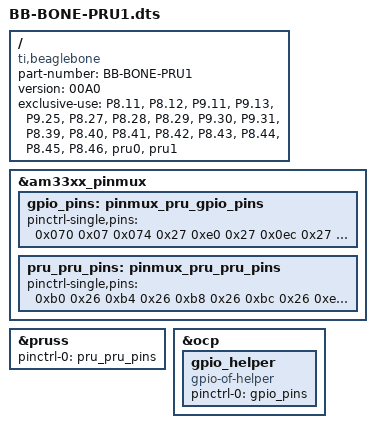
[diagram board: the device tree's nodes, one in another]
/dts-v1/;
/plugin/;

/ {
        compatible = "ti,beaglebone", "ti,beaglebone-black";
        part-number = "BB-BONE-PRU1";
        version = "00A0";
        exclusive-use = "P8.11",                        
                        "P8.12",
                        "P9.11",
                        "P9.13",
                        "P9.25",
                        "P8.27",
                        "P8.28", 
                        "P8.29",
                        "P9.30",
                        "P9.31",
                        "P8.39",
                        "P8.40",
                        "P8.41",
                        "P8.42",
                        "P8.43",
                        "P8.44",
                        "P8.45",
                        "P8.46",
                        "pru0",
                        "pru1";

        fragment@0 {
                target = <&am33xx_pinmux>;
                __overlay__ {

                        gpio_pins: pinmux_pru_gpio_pins {
                                pinctrl-single,pins = <0x070 0x07  //P9_11 MODE7 GPIO output pull-down
                                                       0x074 0x27  //P9_13 MODE7 GPIO input pull-down
                                                       0xe0 0x27   //P8_27 MODE7 GPIO output pull-down $PINS 
                                                       0x0ec 0x27  //P8_30 MODE7 GPIO output pull-down $PINS 59
                                                       0x0d8 0x27  //P8_31 MODE7 GPIO output pull-down $PINS 54
                                                       0x0dc 0x27  //P8_32 MODE7 GPIO output pull-down $PINS 55
                                                       0x0d4 0x27  //P8_33 MODE7 GPIO output pull-down $PINS 53
                                                       0x0cc 0x27  //P8_34 MODE7 GPIO output pull-down $PINS 51
                                                       0x0d0 0x27  //P8_35 MODE7 GPIO output pull-down $PINS 52
                                                       0x0c8 0x27  //P8_36 MODE7 GPIO output pull-down $PINS 50
                                                       0x0c0 0x27  //P8_37 MODE7 GPIO output pull-down $PINS 48
                                                       0x0c4 0x27  //P8_38 MODE7 GPIO output pull-down $PINS 49
                                                      >;
                        };

                        pru_pru_pins: pinmux_pru_pru_pins {
                                pinctrl-single,pins = <// 0x80 0x25 //this pin appears to conflict with the eMMC
                                                       // 0x84 0x25 //this pin appears to conflict with the eMMC
                                                       0xb0 0x26  //P8_41 r31.4  input pull-down $PINS 44
                                                       0xb4 0x26  //P8_42 r31.5  input pull-down $PINS 45
                                                       0xb8 0x26  //P8_39 r31.6  input pull-down $PINS 42
                                                       0xbc 0x26  //P8_40 r31.7  input pull-down $PINS 47
                                                       //0xe0 0x05  //P8_27 r31.8  output pull-down $PINS 56
                                                       0xe4 0x26  //P8_29 r31.9  input pull-down $PINS 57
                                                       0xe8 0x26  //P8_28 r31.10 input pull-down $PINS 58
                                                       0xa0 0x26  //P8_45 r31.0  input pull-down $PINS 40
                                                       0xa4 0x26  //P8_46 r31.1  input pull-down $PINS 41
                                                       0xa8 0x26  //P8_43 r31.2  input pull-down $PINS 42
                                                       0xac 0x26  //P8_44 r31.3  input pull-down $PINS 43

                                                       0x034 0x06  // P8_11 pr1_pru0_pru_r30_15, MODE6 | OUTPUT | PRU
                                                       0x030 0x06  // P8_12 pr1_pru0_pru_r30_14, MODE6 | OUTPUT | PRU
                                                       0x1ac 0x05  // P9_25 pr1_pru0_pru_r30_7, MODE5 | OUTPUT | PRU
                                                       0x190 0x05  // P9_31 pr1_pru0_pru_r30_0, MODE5 | OUTPUT | PRU

                                                       0x1A4 0x26  // P9_27 pr1_pru0_pru_r31_5, MODE6 | INPUT | PRU
                                                       0x19c 0x26  // P9_28 pr1_pru0_pru_r31_3, MODE6 | INPUT | PRU
                                                       0x194 0x26  // P9_29 pr1_pru0_pru_r31_1 , MODE 6 | INPUT | PRU
                                                       0x198 0x26  // P9_30 pr1_pru0_pru_r31_2 , MODE 6 | INPUT | PRU 
                                                       >;
                                                                               };
                };
        };
        fragment@1 {
                target = <&pruss>;
                __overlay__ {
                        status = "okay";
                        pinctrl-names = "default";
                        pinctrl-0 = <&pru_pru_pins>;
                };
        };

       fragment@2 {         // Enable the GPIOs
                target = <&ocp>;
                __overlay__ {
                  gpio_helper {
                        compatible = "gpio-of-helper";
                        status = "okay";
                        pinctrl-names = "default";
                        pinctrl-0 = <&gpio_pins>;
                };
        };
   };
};
